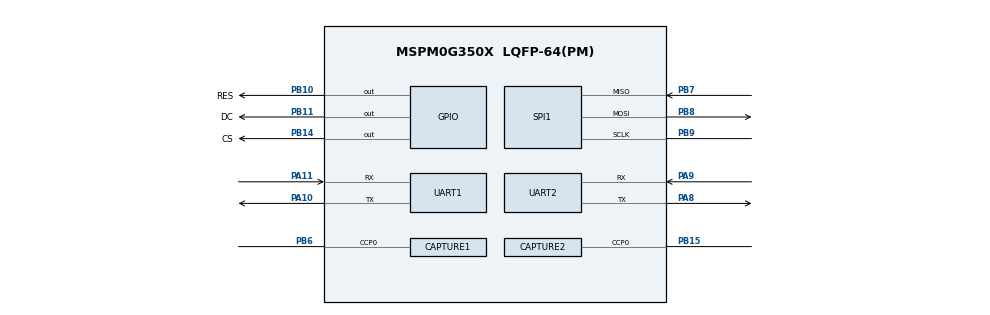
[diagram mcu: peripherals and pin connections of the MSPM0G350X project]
/**
 * @cliArgs --device "MSPM0G350X" --part "Default" --package "LQFP-64(PM)" --product "mspm0_sdk@2.10.00.04"
 * @versions {"tool":"1.27.1+4634"}
 */

/**
 * Import the modules used in this configuration.
 */
const CAPTURE  = scripting.addModule("/ti/driverlib/CAPTURE", {}, false);
const CAPTURE1 = CAPTURE.addInstance();
const CAPTURE2 = CAPTURE.addInstance();
const GPIO     = scripting.addModule("/ti/driverlib/GPIO", {}, false);
const GPIO1    = GPIO.addInstance();
const GPIO2    = GPIO.addInstance();
const GPIO3    = GPIO.addInstance();
const GPIO4    = GPIO.addInstance();
const GPIO5    = GPIO.addInstance();
const PWM      = scripting.addModule("/ti/driverlib/PWM", {}, false);
const PWM1     = PWM.addInstance();
const SPI      = scripting.addModule("/ti/driverlib/SPI", {}, false);
const SPI1     = SPI.addInstance();
const SYSCTL   = scripting.addModule("/ti/driverlib/SYSCTL");
const TIMER    = scripting.addModule("/ti/driverlib/TIMER", {}, false);
const TIMER1   = TIMER.addInstance();
const UART     = scripting.addModule("/ti/driverlib/UART", {}, false);
const UART1    = UART.addInstance();
const UART2    = UART.addInstance();

/**
 * Write custom configuration values to the imported modules.
 */
const divider9       = system.clockTree["UDIV"];
divider9.divideValue = 2;

const mux4       = system.clockTree["EXHFMUX"];
mux4.inputSelect = "EXHFMUX_XTAL";

const mux8       = system.clockTree["HSCLKMUX"];
mux8.inputSelect = "HSCLKMUX_SYSPLL2X";

const mux12       = system.clockTree["SYSPLLMUX"];
mux12.inputSelect = "zSYSPLLMUX_HFCLK";

const pinFunction4        = system.clockTree["HFXT"];
pinFunction4.enable       = true;
pinFunction4.inputFreq    = 40;
pinFunction4.HFXTStartup  = 20;
pinFunction4.HFCLKMonitor = true;

CAPTURE1.$name                              = "ENCODER_0";
CAPTURE1.timerClkPrescale                   = 8;
CAPTURE1.timerPeriod                        = "50 ms";
CAPTURE1.interrupts                         = ["CC0_DN","ZERO"];
CAPTURE1.timerClkDiv                        = 8;
CAPTURE1.peripheral.$assign                 = "TIMG6";
CAPTURE1.peripheral.ccp0Pin.$assign         = "PB6";
CAPTURE1.ccp0PinConfig.hideOutputInversion  = scripting.forceWrite(false);
CAPTURE1.ccp0PinConfig.onlyInternalResistor = scripting.forceWrite(false);
CAPTURE1.ccp0PinConfig.passedPeripheralType = scripting.forceWrite("Digital");
CAPTURE1.ccp0PinConfig.$name                = "ti_driverlib_gpio_GPIOPinGeneric2";
CAPTURE1.ccp0PinConfig.enableConfig         = true;
CAPTURE1.ccp0PinConfig.internalResistor     = "PULL_UP";

const Board = scripting.addModule("/ti/driverlib/Board", {}, false);

CAPTURE2.$name                              = "ENCODER_1";
CAPTURE2.timerClkPrescale                   = 8;
CAPTURE2.timerPeriod                        = "50 ms";
CAPTURE2.interrupts                         = ["CC0_DN","ZERO"];
CAPTURE2.timerClkDiv                        = 8;
CAPTURE2.peripheral.$assign                 = "TIMG7";
CAPTURE2.peripheral.ccp0Pin.$assign         = "PB15";
CAPTURE2.ccp0PinConfig.hideOutputInversion  = scripting.forceWrite(false);
CAPTURE2.ccp0PinConfig.onlyInternalResistor = scripting.forceWrite(false);
CAPTURE2.ccp0PinConfig.passedPeripheralType = scripting.forceWrite("Digital");
CAPTURE2.ccp0PinConfig.$name                = "ti_driverlib_gpio_GPIOPinGeneric3";
CAPTURE2.ccp0PinConfig.enableConfig         = true;
CAPTURE2.ccp0PinConfig.internalResistor     = "PULL_UP";

GPIO1.$name                         = "GPIO_dirA";
GPIO1.port                          = "PORTA";
GPIO1.associatedPins.create(2);
GPIO1.associatedPins[0].$name       = "PIN_26";
GPIO1.associatedPins[0].assignedPin = "26";
GPIO1.associatedPins[0].ioStructure = "SD";
GPIO1.associatedPins[1].$name       = "PIN_27";
GPIO1.associatedPins[1].ioStructure = "SD";
GPIO1.associatedPins[1].assignedPin = "27";

GPIO2.$name                         = "GPIO_dirB";
GPIO2.port                          = "PORTB";
GPIO2.associatedPins.create(2);
GPIO2.associatedPins[0].ioStructure = "SD";
GPIO2.associatedPins[0].$name       = "PIN_4";
GPIO2.associatedPins[0].assignedPin = "4";
GPIO2.associatedPins[1].ioStructure = "SD";
GPIO2.associatedPins[1].$name       = "PIN_20";
GPIO2.associatedPins[1].assignedPin = "20";

GPIO3.$name                              = "GPIO_ENC_DIR";
GPIO3.port                               = "PORTB";
GPIO3.associatedPins[0].$name            = "ENC_B1";
GPIO3.associatedPins[0].direction        = "INPUT";
GPIO3.associatedPins[0].assignedPin      = "12";
GPIO3.associatedPins[0].internalResistor = "PULL_UP";

GPIO4.$name                              = "GPIO_ENC2_DIR";
GPIO4.port                               = "PORTB";
GPIO4.associatedPins[0].$name            = "ENC_B2";
GPIO4.associatedPins[0].direction        = "INPUT";
GPIO4.associatedPins[0].assignedPin      = "13";
GPIO4.associatedPins[0].internalResistor = "PULL_UP";

GPIO5.$name                         = "GPIO_oled";
GPIO5.port                          = "PORTB";
GPIO5.associatedPins.create(3);
GPIO5.associatedPins[0].$name       = "RES";
GPIO5.associatedPins[0].ioStructure = "SD";
GPIO5.associatedPins[0].assignedPin = "10";
GPIO5.associatedPins[0].pin.$assign = "PB10";
GPIO5.associatedPins[1].$name       = "DC";
GPIO5.associatedPins[1].ioStructure = "SD";
GPIO5.associatedPins[1].assignedPin = "11";
GPIO5.associatedPins[1].pin.$assign = "PB11";
GPIO5.associatedPins[2].$name       = "CS";
GPIO5.associatedPins[2].ioStructure = "SD";
GPIO5.associatedPins[2].assignedPin = "14";
GPIO5.associatedPins[2].pin.$assign = "PB14";

PWM1.$name               = "PWM_0";
PWM1.timerCount          = 40000;
PWM1.PWM_CHANNEL_0.$name = "ti_driverlib_pwm_PWMTimerCC0";
PWM1.PWM_CHANNEL_1.$name = "ti_driverlib_pwm_PWMTimerCC1";
PWM1.ccp0PinConfig.$name = "ti_driverlib_gpio_GPIOPinGeneric0";
PWM1.ccp1PinConfig.$name = "ti_driverlib_gpio_GPIOPinGeneric1";

SPI1.$name                              = "SPI_oled";
SPI1.frameFormat                        = "MOTO3";
SPI1.sclkPinConfig.direction            = scripting.forceWrite("OUTPUT");
SPI1.sclkPinConfig.onlyInternalResistor = scripting.forceWrite(false);
SPI1.sclkPinConfig.passedPeripheralType = scripting.forceWrite("Digital");
SPI1.sclkPinConfig.$name                = "ti_driverlib_gpio_GPIOPinGeneric6";
SPI1.mosiPinConfig.direction            = scripting.forceWrite("OUTPUT");
SPI1.mosiPinConfig.hideOutputInversion  = scripting.forceWrite(false);
SPI1.mosiPinConfig.onlyInternalResistor = scripting.forceWrite(false);
SPI1.mosiPinConfig.passedPeripheralType = scripting.forceWrite("Digital");
SPI1.mosiPinConfig.$name                = "ti_driverlib_gpio_GPIOPinGeneric7";
SPI1.misoPinConfig.onlyInternalResistor = scripting.forceWrite(false);
SPI1.misoPinConfig.passedPeripheralType = scripting.forceWrite("Digital");
SPI1.misoPinConfig.$name                = "ti_driverlib_gpio_GPIOPinGeneric8";
SPI1.peripheral.$assign                 = "SPI1";
SPI1.peripheral.sclkPin.$assign         = "PB9";
SPI1.peripheral.mosiPin.$assign         = "PB8";
SPI1.peripheral.misoPin.$assign         = "PB7";

SYSCTL.MCLKSource            = "HSCLK";
SYSCTL.clockTreeEn           = true;
SYSCTL.SYSPLL_CLK2XDiv       = 1;
SYSCTL.SYSPLL_CLK0En         = true;
SYSCTL.forceDefaultClkConfig = true;
SYSCTL.validateClkStatus     = true;

TIMER1.timerPeriod        = "1 ms";
TIMER1.interrupts         = ["ZERO"];
TIMER1.timerClkPrescale   = 8;
TIMER1.$name              = "TIMER_G0";
TIMER1.timerMode          = "PERIODIC_UP";
TIMER1.peripheral.$assign = "TIMG0";

UART1.$name                    = "UART_0";
UART1.peripheral.rxPin.$assign = "PA11";
UART1.peripheral.txPin.$assign = "PA10";
UART1.txPinConfig.$name        = "ti_driverlib_gpio_GPIOPinGeneric4";
UART1.rxPinConfig.$name        = "ti_driverlib_gpio_GPIOPinGeneric5";

UART2.$name                            = "UART_bluetooth";
UART2.targetBaudRate                   = 19200;
UART2.peripheral.rxPin.$assign         = "PA9";
UART2.peripheral.txPin.$assign         = "PA8";
UART2.txPinConfig.direction            = scripting.forceWrite("OUTPUT");
UART2.txPinConfig.hideOutputInversion  = scripting.forceWrite(false);
UART2.txPinConfig.onlyInternalResistor = scripting.forceWrite(false);
UART2.txPinConfig.passedPeripheralType = scripting.forceWrite("Digital");
UART2.txPinConfig.$name                = "ti_driverlib_gpio_GPIOPinGeneric9";
UART2.rxPinConfig.hideOutputInversion  = scripting.forceWrite(false);
UART2.rxPinConfig.onlyInternalResistor = scripting.forceWrite(false);
UART2.rxPinConfig.passedPeripheralType = scripting.forceWrite("Digital");
UART2.rxPinConfig.$name                = "ti_driverlib_gpio_GPIOPinGeneric10";

/**
 * Pinmux solution for unlocked pins/peripherals. This ensures that minor changes to the automatic solver in a future
 * version of the tool will not impact the pinmux you originally saw.  These lines can be completely deleted in order to
 * re-solve from scratch.
 */
pinFunction4.peripheral.$suggestSolution           = "SYSCTL";
pinFunction4.peripheral.hfxInPin.$suggestSolution  = "PA5";
pinFunction4.peripheral.hfxOutPin.$suggestSolution = "PA6";
Board.peripheral.$suggestSolution                  = "DEBUGSS";
Board.peripheral.swclkPin.$suggestSolution         = "PA20";
Board.peripheral.swdioPin.$suggestSolution         = "PA19";
GPIO1.associatedPins[0].pin.$suggestSolution       = "PA26";
GPIO1.associatedPins[1].pin.$suggestSolution       = "PA27";
GPIO2.associatedPins[0].pin.$suggestSolution       = "PB4";
GPIO2.associatedPins[1].pin.$suggestSolution       = "PB20";
GPIO3.associatedPins[0].pin.$suggestSolution       = "PB12";
GPIO4.associatedPins[0].pin.$suggestSolution       = "PB13";
PWM1.peripheral.$suggestSolution                   = "TIMA0";
PWM1.peripheral.ccp0Pin.$suggestSolution           = "PA0";
PWM1.peripheral.ccp1Pin.$suggestSolution           = "PA1";
UART1.peripheral.$suggestSolution                  = "UART0";
UART2.peripheral.$suggestSolution                  = "UART1";
